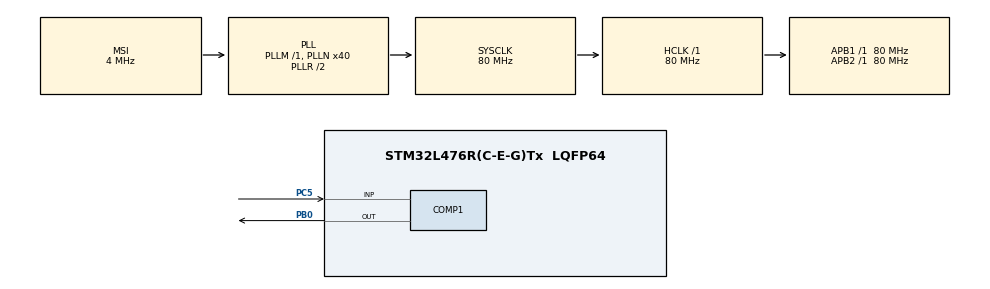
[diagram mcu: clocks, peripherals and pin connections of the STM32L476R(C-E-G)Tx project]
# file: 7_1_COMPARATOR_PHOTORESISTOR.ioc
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COMP1.OutputPol=COMP_OUTPUTPOL_INVERTED
Mcu.Family=STM32L4
Mcu.Name=STM32L476R(C-E-G)Tx
Mcu.Package=LQFP64
NVIC.PriorityGroup=NVIC_PRIORITYGROUP_4
PA13\ (JTMS-SWDIO).Mode=Serial_Wire
PA13\ (JTMS-SWDIO).Signal=SYS_JTMS-SWDIO
PA14\ (JTCK-SWCLK).Mode=Serial_Wire
PA14\ (JTCK-SWCLK).Signal=SYS_JTCK-SWCLK
PB0.Mode=ExternalOutput
PB0.Signal=COMP1_OUT
PC5.Mode=INP
PC5.Signal=COMP1_INP
ProjectManager.HeapSize=0x200
ProjectManager.StackSize=0x400
ProjectManager.TargetToolchain=STM32CubeIDE
RCC.AHBFreq_Value=80000000
RCC.APB1Freq_Value=80000000
RCC.APB1TimFreq_Value=80000000
RCC.APB2Freq_Value=80000000
RCC.APB2TimFreq_Value=80000000
RCC.CortexFreq_Value=80000000
RCC.HCLKFreq_Value=80000000
RCC.HSE_VALUE=8000000
RCC.HSI_VALUE=16000000
RCC.LSE_VALUE=32768
RCC.MSI_VALUE=4000000
RCC.PLLN=40
RCC.SYSCLKFreq_VALUE=80000000
RCC.SYSCLKSource=RCC_SYSCLKSOURCE_PLLCLK
RCC.VCOOutputFreq_Value=160000000
VP_COMP1_VS_DACOUT1.Mode=INM_DACOUT1
VP_DAC1_VS_DACI1.Mode=DAC_OUT1_Int
board=custom

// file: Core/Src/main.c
/* USER CODE BEGIN Header */
/**
  ******************************************************************************
  * @file           : main.c
  * @brief          : Main program body
  ******************************************************************************
  * @attention
  *
  * Copyright (c) 2024 STMicroelectronics.
  * All rights reserved.
  *
  * This software is licensed under terms that can be found in the LICENSE file
  * in the root directory of this software component.
  * If no LICENSE file comes with this software, it is provided AS-IS.
  *
  ******************************************************************************
  */
/* USER CODE END Header */
#include "main.h"

COMP_HandleTypeDef hcomp1;

DAC_HandleTypeDef hdac1;

void SystemClock_Config(void);
static void MX_GPIO_Init(void);
static void MX_COMP1_Init(void);
static void MX_DAC1_Init(void);

int main(void)
{

  /* MCU Configuration--------------------------------------------------------*/

  /* Reset of all peripherals, Initializes the Flash interface and the Systick. */
  HAL_Init();

  /* Configure the system clock */
  SystemClock_Config();

  /* Initialize all configured peripherals */
  MX_GPIO_Init();
  MX_COMP1_Init();
  MX_DAC1_Init();
  /* USER CODE BEGIN 2 */

  HAL_DAC_Start(&hdac1, DAC_CHANNEL_1);
  HAL_DAC_SetValue(&hdac1, DAC_CHANNEL_1, DAC_ALIGN_12B_R, 1650);

  HAL_COMP_Start(&hcomp1);

  /* USER CODE END 2 */

  /* Infinite loop */
  while (1)
  {

  }
}

void SystemClock_Config(void)
{
  RCC_OscInitTypeDef RCC_OscInitStruct = {0};
  RCC_ClkInitTypeDef RCC_ClkInitStruct = {0};

  /** Configure the main internal regulator output voltage
  */
  if (HAL_PWREx_ControlVoltageScaling(PWR_REGULATOR_VOLTAGE_SCALE1) != HAL_OK)
  {
    Error_Handler();
  }

  /** Initializes the RCC Oscillators according to the specified parameters
  * in the RCC_OscInitTypeDef structure.
  */
  RCC_OscInitStruct.OscillatorType = RCC_OSCILLATORTYPE_MSI;
  RCC_OscInitStruct.MSIState = RCC_MSI_ON;
  RCC_OscInitStruct.MSICalibrationValue = 0;
  RCC_OscInitStruct.MSIClockRange = RCC_MSIRANGE_6;
  RCC_OscInitStruct.PLL.PLLState = RCC_PLL_ON;
  RCC_OscInitStruct.PLL.PLLSource = RCC_PLLSOURCE_MSI;
  RCC_OscInitStruct.PLL.PLLM = 1;
  RCC_OscInitStruct.PLL.PLLN = 40;
  RCC_OscInitStruct.PLL.PLLP = RCC_PLLP_DIV7;
  RCC_OscInitStruct.PLL.PLLQ = RCC_PLLQ_DIV2;
  RCC_OscInitStruct.PLL.PLLR = RCC_PLLR_DIV2;
  if (HAL_RCC_OscConfig(&RCC_OscInitStruct) != HAL_OK)
  {
    Error_Handler();
  }

  /** Initializes the CPU, AHB and APB buses clocks
  */
  RCC_ClkInitStruct.ClockType = RCC_CLOCKTYPE_HCLK|RCC_CLOCKTYPE_SYSCLK
                              |RCC_CLOCKTYPE_PCLK1|RCC_CLOCKTYPE_PCLK2;
  RCC_ClkInitStruct.SYSCLKSource = RCC_SYSCLKSOURCE_PLLCLK;
  RCC_ClkInitStruct.AHBCLKDivider = RCC_SYSCLK_DIV1;
  RCC_ClkInitStruct.APB1CLKDivider = RCC_HCLK_DIV1;
  RCC_ClkInitStruct.APB2CLKDivider = RCC_HCLK_DIV1;

  if (HAL_RCC_ClockConfig(&RCC_ClkInitStruct, FLASH_LATENCY_4) != HAL_OK)
  {
    Error_Handler();
  }
}

static void MX_COMP1_Init(void)
{

  hcomp1.Instance = COMP1;
  hcomp1.Init.InvertingInput = COMP_INPUT_MINUS_DAC1_CH1;
  hcomp1.Init.NonInvertingInput = COMP_INPUT_PLUS_IO1;
  hcomp1.Init.OutputPol = COMP_OUTPUTPOL_INVERTED;
  hcomp1.Init.Hysteresis = COMP_HYSTERESIS_NONE;
  hcomp1.Init.BlankingSrce = COMP_BLANKINGSRC_NONE;
  hcomp1.Init.Mode = COMP_POWERMODE_HIGHSPEED;
  hcomp1.Init.WindowMode = COMP_WINDOWMODE_DISABLE;
  hcomp1.Init.TriggerMode = COMP_TRIGGERMODE_NONE;
  if (HAL_COMP_Init(&hcomp1) != HAL_OK)
  {
    Error_Handler();
  }

}

static void MX_DAC1_Init(void)
{

  DAC_ChannelConfTypeDef sConfig = {0};

  /** DAC Initialization
  */
  hdac1.Instance = DAC1;
  if (HAL_DAC_Init(&hdac1) != HAL_OK)
  {
    Error_Handler();
  }

  /** DAC channel OUT1 config
  */
  sConfig.DAC_SampleAndHold = DAC_SAMPLEANDHOLD_DISABLE;
  sConfig.DAC_Trigger = DAC_TRIGGER_NONE;
  sConfig.DAC_OutputBuffer = DAC_OUTPUTBUFFER_DISABLE;
  sConfig.DAC_ConnectOnChipPeripheral = DAC_CHIPCONNECT_ENABLE;
  sConfig.DAC_UserTrimming = DAC_TRIMMING_FACTORY;
  if (HAL_DAC_ConfigChannel(&hdac1, &sConfig, DAC_CHANNEL_1) != HAL_OK)
  {
    Error_Handler();
  }

}

static void MX_GPIO_Init(void)
{

  /* GPIO Ports Clock Enable */
  __HAL_RCC_GPIOC_CLK_ENABLE();
  __HAL_RCC_GPIOB_CLK_ENABLE();
  __HAL_RCC_GPIOA_CLK_ENABLE();

}

void Error_Handler(void)
{
  __disable_irq();
  while (1)
  {
  }
}
